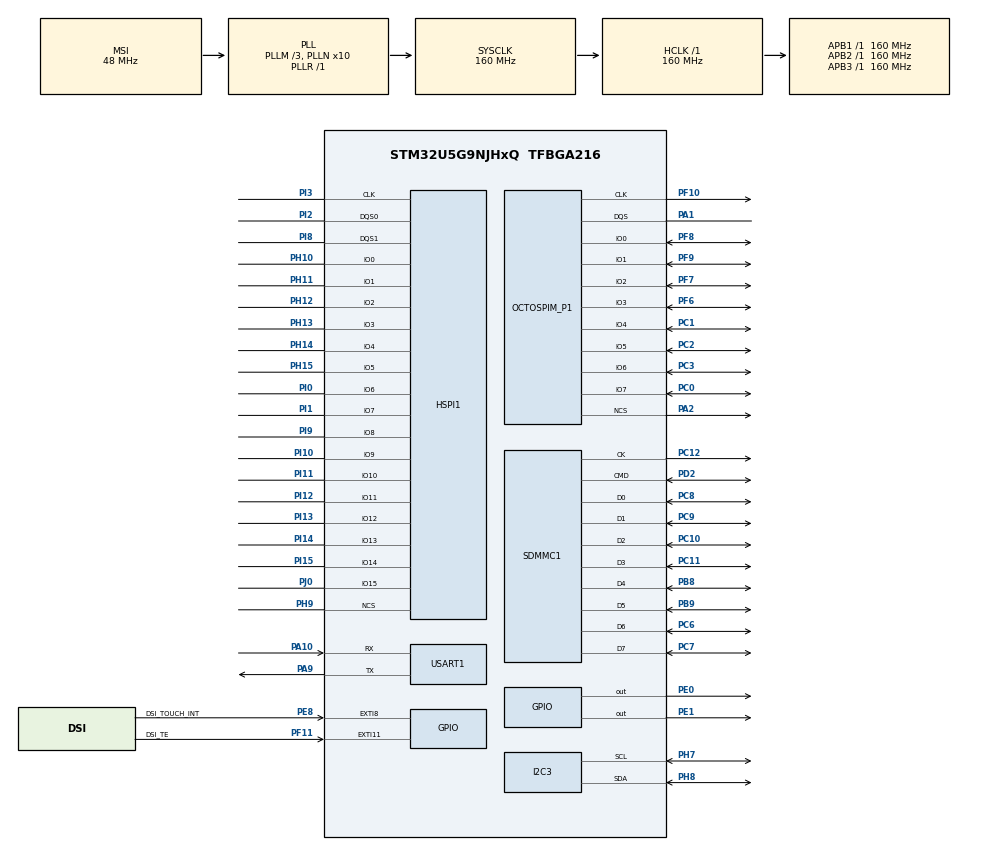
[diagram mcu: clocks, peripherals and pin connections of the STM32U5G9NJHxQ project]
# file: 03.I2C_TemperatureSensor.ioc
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CORTEX_M33_NS.userName=CORTEX_M33
DSI_CKN.Mode=DSIHost_Standalone
DSI_CKN.Signal=DSIHOST_CKN
DSI_CKP.Mode=DSIHost_Standalone
DSI_CKP.Signal=DSIHOST_CKP
DSI_D0N.Mode=DSIHost_Standalone
DSI_D0N.Signal=DSIHOST_D0N
DSI_D0P.Mode=DSIHost_Standalone
DSI_D0P.Signal=DSIHOST_D0P
DSI_D1N.Mode=DSIHost_Standalone
DSI_D1N.Signal=DSIHOST_D1N
DSI_D1P.Mode=DSIHost_Standalone
DSI_D1P.Signal=DSIHOST_D1P
I2C3.Timing=0x30909DEC
Mcu.Family=STM32U5
Mcu.Name=STM32U5G9NJHxQ
Mcu.Package=TFBGA216
NVIC.GFXMMU_IRQn=true\:0\:0\:false\:false\:true\:true\:true\:true
NVIC.GFXTIM_IRQn=true\:0\:0\:false\:false\:true\:true\:true\:true
NVIC.PriorityGroup=NVIC_PRIORITYGROUP_4
NVIC.USART1_IRQn=true\:0\:0\:false\:false\:true\:true\:true\:true
PA1.Mode=OCTOSPI1_Port1_DQS
PA1.Signal=OCTOSPIM_P1_DQS
PA10.Mode=Asynchronous
PA10.Signal=USART1_RX
PA2.Mode=OCTOSPI1_Port1_NCS
PA2.Signal=OCTOSPIM_P1_NCS
PA9.Mode=Asynchronous
PA9.Signal=USART1_TX
PB8.Mode=mmc_8_bits_Wide_bus
PB8.Signal=SDMMC1_D4
PB9.Mode=mmc_8_bits_Wide_bus
PB9.Signal=SDMMC1_D5
PC0.Mode=OCTOSPI1_IOH_Port1H
PC0.Signal=OCTOSPIM_P1_IO7
PC1.Mode=OCTOSPI1_IOH_Port1H
PC1.Signal=OCTOSPIM_P1_IO4
PC10.Mode=mmc_8_bits_Wide_bus
PC10.Signal=SDMMC1_D2
PC11.Mode=mmc_8_bits_Wide_bus
PC11.Signal=SDMMC1_D3
PC12.Mode=mmc_8_bits_Wide_bus
PC12.Signal=SDMMC1_CK
PC14-OSC32_IN\ (PC14).Mode=LSE-External-Oscillator
PC14-OSC32_IN\ (PC14).Signal=RCC_OSC32_IN
PC15-OSC32_OUT\ (PC15).Mode=LSE-External-Oscillator
PC15-OSC32_OUT\ (PC15).Signal=RCC_OSC32_OUT
PC2.Mode=OCTOSPI1_IOH_Port1H
PC2.Signal=OCTOSPIM_P1_IO5
PC3.Mode=OCTOSPI1_IOH_Port1H
PC3.Signal=OCTOSPIM_P1_IO6
PC6.Mode=mmc_8_bits_Wide_bus
PC6.Signal=SDMMC1_D6
PC7.Mode=mmc_8_bits_Wide_bus
PC7.Signal=SDMMC1_D7
PC8.Mode=mmc_8_bits_Wide_bus
PC8.Signal=SDMMC1_D0
PC9.Mode=mmc_8_bits_Wide_bus
PC9.Signal=SDMMC1_D1
PD2.Mode=mmc_8_bits_Wide_bus
PD2.Signal=SDMMC1_CMD
PE0.Signal=GPIO_Output
PE1.Signal=GPIO_Output
PE8.GPIO_Label=DSI_TOUCH_INT
PE8.Signal=GPXTI8
PF10.Mode=O1_P1_CLK
PF10.Signal=OCTOSPIM_P1_CLK
PF11.GPIO_Label=DSI_TE
PF11.Signal=GPXTI11
PF6.Mode=OCTOSPI1_IOL_Port1L
PF6.Signal=OCTOSPIM_P1_IO3
PF7.Mode=OCTOSPI1_IOL_Port1L
PF7.Signal=OCTOSPIM_P1_IO2
PF8.Mode=OCTOSPI1_IOL_Port1L
PF8.Signal=OCTOSPIM_P1_IO0
PF9.Mode=OCTOSPI1_IOL_Port1L
PF9.Signal=OCTOSPIM_P1_IO1
PH0-OSC_IN\ (PH0).Mode=HSE-External-Oscillator
PH0-OSC_IN\ (PH0).Signal=RCC_OSC_IN
PH1-OSC_OUT\ (PH1).Mode=HSE-External-Oscillator
PH1-OSC_OUT\ (PH1).Signal=RCC_OSC_OUT
PH10.Mode=hexa_mode
PH10.Signal=HSPI1_IO0
PH11.Mode=hexa_mode
PH11.Signal=HSPI1_IO1
PH12.Mode=hexa_mode
PH12.Signal=HSPI1_IO2
PH13.Mode=hexa_mode
PH13.Signal=HSPI1_IO3
PH14.Mode=hexa_mode
PH14.Signal=HSPI1_IO4
PH15.Mode=hexa_mode
PH15.Signal=HSPI1_IO5
PH7.Mode=I2C
PH7.Signal=I2C3_SCL
PH8.Mode=I2C
PH8.Signal=I2C3_SDA
PH9.Mode=hexa_mode
PH9.Signal=HSPI1_NCS
PI0.Mode=hexa_mode
PI0.Signal=HSPI1_IO6
PI1.Mode=hexa_mode
PI1.Signal=HSPI1_IO7
PI10.Mode=hexa_mode
PI10.Signal=HSPI1_IO9
PI11.Mode=hexa_mode
PI11.Signal=HSPI1_IO10
PI12.Mode=hexa_mode
PI12.Signal=HSPI1_IO11
PI13.Mode=hexa_mode
PI13.Signal=HSPI1_IO12
PI14.Mode=hexa_mode
PI14.Signal=HSPI1_IO13
PI15.Mode=hexa_mode
PI15.Signal=HSPI1_IO14
PI2.Mode=hexa_mode
PI2.Signal=HSPI1_DQS0
PI3.Mode=hexa_mode
PI3.Signal=HSPI1_CLK
PI8.Mode=hexa_mode
PI8.Signal=HSPI1_DQS1
PI9.Mode=hexa_mode
PI9.Signal=HSPI1_IO8
PJ0.Mode=hexa_mode
PJ0.Signal=HSPI1_IO15
PWR.PowerMode=PWR_SMPS_SUPPLY
ProjectManager.HeapSize=0x200
ProjectManager.StackSize=0x400
ProjectManager.TargetToolchain=STM32CubeIDE
RCC.ADCFreq_Value=16000000
RCC.AHBFreq_Value=160000000
RCC.APB1Freq_Value=160000000
RCC.APB1TimFreq_Value=160000000
RCC.APB2Freq_Value=160000000
RCC.APB2TimFreq_Value=160000000
RCC.APB3Freq_Value=160000000
RCC.CortexFreq_Value=160000000
RCC.EPOD_VALUE=48000000
RCC.HCLKFreq_Value=160000000
RCC.HSE_VALUE=16000000
RCC.HSI48_VALUE=48000000
RCC.HSI_VALUE=16000000
RCC.LSIDIV_VALUE=32000
RCC.MSIClockRange=RCC_MSIRANGE_0
RCC.MSI_VALUE=48000000
RCC.PLL1R=1
RCC.PLL2M=4
RCC.PLL2N=125
RCC.PLL2R=24
RCC.PLL2Source=RCC_PLLSOURCE_HSE
RCC.PLL3M=4
RCC.PLL3N=125
RCC.PLL3P=8
RCC.PLL3R=24
RCC.PLL3Source=RCC_PLLSOURCE_HSE
RCC.PLLDSIIDF=DSI_PLL_IN_DIV4
RCC.PLLDSINDIV=125
RCC.PLLDSIODF=DSI_PLL_OUT_DIV2
RCC.PLLFRACN=0
RCC.PLLM=3
RCC.PLLN=10
RCC.SYSCLKFreq_VALUE=160000000
RCC.SYSCLKSource=RCC_SYSCLKSOURCE_PLLCLK
RCC.VCOOutputFreq_Value=160000000
USART1.VirtualMode-Asynchronous=VM_ASYNC
VP_DMA2D_VS_DMA2D.Mode=DMA2D_Activate
VP_GFXMMU_VS_GFXMMU.Mode=GFXMMU_Activate
VP_GFXTIM_VS_GFXTIM.Mode=GFXTIM_Activate
VP_ICACHE_VS_ICACHE.Mode=DirectMappedCache
VP_LPBAMQUEUE_VS_QUEUE.Mode=QUEUEMODE
VP_LPBAM_VS_SIG1.Mode=SmartRun
VP_LPBAM_VS_SIG4.Mode=LPDMA1
VP_LTDC_DSIMode.Mode=RGB888
VP_MEMORYMAP_VS_MEMORYMAP.Mode=CurAppReg
VP_OCTOSPI1_VS_octo.Mode=octo_mode
VP_PWR_VS_DBSignals.Mode=DisableDeadBatterySignals
VP_PWR_VS_LPOM.Mode=PowerOptimisation
VP_PWR_VS_SECSignals.Mode=Security/Privilege
board=custom

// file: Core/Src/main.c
/* USER CODE BEGIN Header */
/**
  ******************************************************************************
  * @file           : main.c
  * @brief          : Main program body
  ******************************************************************************
  * @attention
  *
  * Copyright (c) 2024 STMicroelectronics.
  * All rights reserved.
  *
  * This software is licensed under terms that can be found in the LICENSE file
  * in the root directory of this software component.
  * If no LICENSE file comes with this software, it is provided AS-IS.
  *
  ******************************************************************************
  */
/* USER CODE END Header */
#include "main.h"
#include "gfxmmu_lut.h"
#include "dma2d.h"
#include "dsihost.h"
#include "gfxmmu.h"
#include "gfxtim.h"
#include "hspi.h"
#include "i2c.h"
#include "icache.h"
#include "ltdc.h"
#include "memorymap.h"
#include "octospi.h"
#include "sdmmc.h"
#include "usart.h"
#include "gpio.h"

/* USER CODE BEGIN PV */
int count = 0;

/* USER CODE END PV */

void SystemClock_Config(void);
static void SystemPower_Config(void);

/* USER CODE BEGIN 0 */
int _write(int file, char* pData, int len)
{
	HAL_UART_Transmit(&huart1, (uint8_t*)pData, len, 10);
	return len;
}
/* USER CODE END 0 */

int main(void)
{

  /* MCU Configuration--------------------------------------------------------*/

  /* Reset of all peripherals, Initializes the Flash interface and the Systick. */
  HAL_Init();

  /* Configure the System Power */
  SystemPower_Config();

  /* Configure the system clock */
  SystemClock_Config();

  /* Initialize all configured peripherals */
  MX_GPIO_Init();
  MX_I2C3_Init();
  MX_USART1_UART_Init();
  MX_ICACHE_Init();
  MX_SDMMC1_MMC_Init();
  MX_OCTOSPI1_Init();
  MX_HSPI1_Init();
  MX_DSIHOST_DSI_Init();
  MX_LTDC_Init();
  MX_DMA2D_Init();
  MX_GFXMMU_Init();
  MX_GFXTIM_Init();

  /* Infinite loop */
  /* USER CODE BEGIN WHILE */
  while (1)
  {

	  count++;
	  printf("[%d]\r\n", count);
	  HAL_Delay(1000);
    /* USER CODE END WHILE */

  }
}

void SystemClock_Config(void)
{
  RCC_OscInitTypeDef RCC_OscInitStruct = {0};
  RCC_ClkInitTypeDef RCC_ClkInitStruct = {0};

  /** Configure the main internal regulator output voltage
  */
  if (HAL_PWREx_ControlVoltageScaling(PWR_REGULATOR_VOLTAGE_SCALE1) != HAL_OK)
  {
    Error_Handler();
  }

  /** Initializes the CPU, AHB and APB buses clocks
  */
  RCC_OscInitStruct.OscillatorType = RCC_OSCILLATORTYPE_HSE|RCC_OSCILLATORTYPE_MSI;
  RCC_OscInitStruct.HSEState = RCC_HSE_ON;
  RCC_OscInitStruct.MSIState = RCC_MSI_ON;
  RCC_OscInitStruct.MSICalibrationValue = RCC_MSICALIBRATION_DEFAULT;
  RCC_OscInitStruct.MSIClockRange = RCC_MSIRANGE_0;
  RCC_OscInitStruct.PLL.PLLState = RCC_PLL_ON;
  RCC_OscInitStruct.PLL.PLLSource = RCC_PLLSOURCE_MSI;
  RCC_OscInitStruct.PLL.PLLMBOOST = RCC_PLLMBOOST_DIV4;
  RCC_OscInitStruct.PLL.PLLM = 3;
  RCC_OscInitStruct.PLL.PLLN = 10;
  RCC_OscInitStruct.PLL.PLLP = 2;
  RCC_OscInitStruct.PLL.PLLQ = 2;
  RCC_OscInitStruct.PLL.PLLR = 1;
  RCC_OscInitStruct.PLL.PLLRGE = RCC_PLLVCIRANGE_1;
  RCC_OscInitStruct.PLL.PLLFRACN = 0;
  if (HAL_RCC_OscConfig(&RCC_OscInitStruct) != HAL_OK)
  {
    Error_Handler();
  }

  /** Initializes the CPU, AHB and APB buses clocks
  */
  RCC_ClkInitStruct.ClockType = RCC_CLOCKTYPE_HCLK|RCC_CLOCKTYPE_SYSCLK
                              |RCC_CLOCKTYPE_PCLK1|RCC_CLOCKTYPE_PCLK2
                              |RCC_CLOCKTYPE_PCLK3;
  RCC_ClkInitStruct.SYSCLKSource = RCC_SYSCLKSOURCE_PLLCLK;
  RCC_ClkInitStruct.AHBCLKDivider = RCC_SYSCLK_DIV1;
  RCC_ClkInitStruct.APB1CLKDivider = RCC_HCLK_DIV1;
  RCC_ClkInitStruct.APB2CLKDivider = RCC_HCLK_DIV1;
  RCC_ClkInitStruct.APB3CLKDivider = RCC_HCLK_DIV1;

  if (HAL_RCC_ClockConfig(&RCC_ClkInitStruct, FLASH_LATENCY_4) != HAL_OK)
  {
    Error_Handler();
  }
}

/**
  * @brief Power Configuration
  * @retval None
  */
static void SystemPower_Config(void)
{

  /*
   * Disable the internal Pull-Up in Dead Battery pins of UCPD peripheral
   */
  HAL_PWREx_DisableUCPDDeadBattery();

  /*
   * Switch to SMPS regulator instead of LDO
   */
  if (HAL_PWREx_ConfigSupply(PWR_SMPS_SUPPLY) != HAL_OK)
  {
    Error_Handler();
  }
}

void Error_Handler(void)
{
  __disable_irq();
  while (1)
  {
  }
}
